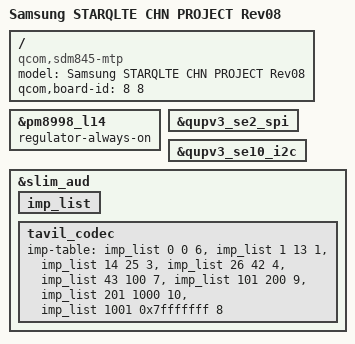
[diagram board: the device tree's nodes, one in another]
/* Copyright (c) 2016-2017, The Linux Foundation. All rights reserved.
 *
 * This program is free software; you can redistribute it and/or modify
 * it under the terms of the GNU General Public License version 2 and
 * only version 2 as published by the Free Software Foundation.
 *
 * This program is distributed in the hope that it will be useful,
 * but WITHOUT ANY WARRANTY; without even the implied warranty of
 * MERCHANTABILITY or FITNESS FOR A PARTICULAR PURPOSE.  See the
 * GNU General Public License for more details.
 */

/dts-v1/;

#include "../qcom/sdm845-v2.dtsi"
#include "../qcom/sdm845-mtp.dtsi"
#include "sdm845-sec-common.dtsi"
#include "sdm845-sec-starqlte-pm-common.dtsi"
#include "sdm845-sec-starqlte-pm-r07.dtsi"
#include "sdm845-sec-starqlte-r08.dtsi"
#include "sdm845-sec-starqlte-chn-pinctrl-r08.dtsi"
#include "battery-data-starq-md05-common.dtsi"
#include "sdm845-sec-starqlte-display-r01.dtsi"
#include "sdm845-sec-starqlte-displayport-r00.dtsi"
#include "sdm845-sec-starqlte-fingerprint-sensor-r05.dtsi"
#include "sdm845-sec-starqlte-mst-r00.dtsi"
#include "sdm845-camera-sensor-starqlte-r06.dtsi"
#include "sdm845-starq-max77705.dtsi"

/ {
	model = "Samsung STARQLTE CHN PROJECT Rev08";
	compatible = "qcom,sdm845-mtp", "qcom,sdm845", "qcom,mtp";
	qcom,board-id = <8 8>;
};

&pm8998_l14 {
	regulator-always-on;
};

&qupv3_se2_spi {
	status = "ok";
	/delete-node/ ese_spi@0;
};

&qupv3_se10_i2c {
	status = "ok";
	/delete-node/ pn547@2B;
};

&slim_aud {
	imp_list: imp_list {
		#list-imp-cells = <3>;
	};

	tavil_codec {
		imp-table = <&imp_list 0 0 6>,
				 <&imp_list 1 13 1>,
				 <&imp_list 14 25 3>,
				 <&imp_list 26 42 4>,
				 <&imp_list 43 100 7>,
				 <&imp_list 101 200 9>,
				 <&imp_list 201 1000 10>,
				 <&imp_list 1001 0x7fffffff 8>;
	};
};
